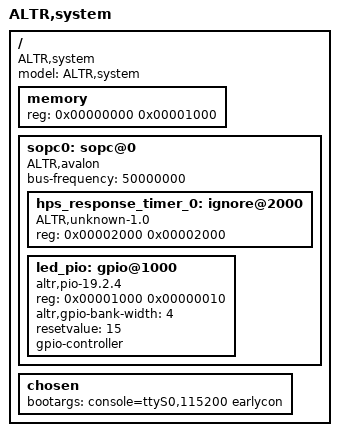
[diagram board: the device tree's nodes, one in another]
/*
 * This devicetree is generated by sopc2dts version 0.1.dev37+gf6edb8b6f.d20260704
 * Original sopc2dts by Walter Goossens <waltergoossens@home.nl>
 * Python port by Laurence <laurence@anodes4life.com>
 * https://github.com/LaurenceA4L/sopc2dts
 */
/dts-v1/;

/ {
	model = "ALTR,system";
	compatible = "ALTR,system";
	#address-cells = <1>;
	#size-cells = <1>;

	memory {
		device_type = "memory";
		reg = <0x00000000 0x00001000>;
	}; //end memory

	sopc0: sopc@0 {
		device_type = "soc";
		ranges;
		#address-cells = <1>;
		#size-cells = <1>;
		compatible = "ALTR,avalon", "simple-bus";
		bus-frequency = <50000000>;

		hps_response_timer_0: ignore@2000 {
			compatible = "ALTR,unknown-1.0";
			reg = <0x00002000 0x00002000>;
		}; //end ignore@2000 (hps_response_timer_0)

		led_pio: gpio@1000 {
			compatible = "altr,pio-19.2.4", "altr,pio-1.0";
			reg = <0x00001000 0x00000010>;
			altr,gpio-bank-width = <4>;	/* embeddedsw.dts.params.altr,gpio-bank-width type NUMBER */
			resetvalue = <15>;	/* embeddedsw.dts.params.resetvalue type NUMBER */
			#gpio-cells = <2>;
			gpio-controller;
		}; //end gpio@1000 (led_pio)
	}; //end sopc@0 (sopc0)

	chosen {
		bootargs = "console=ttyS0,115200 earlycon";
	}; //end chosen
}; //end /
